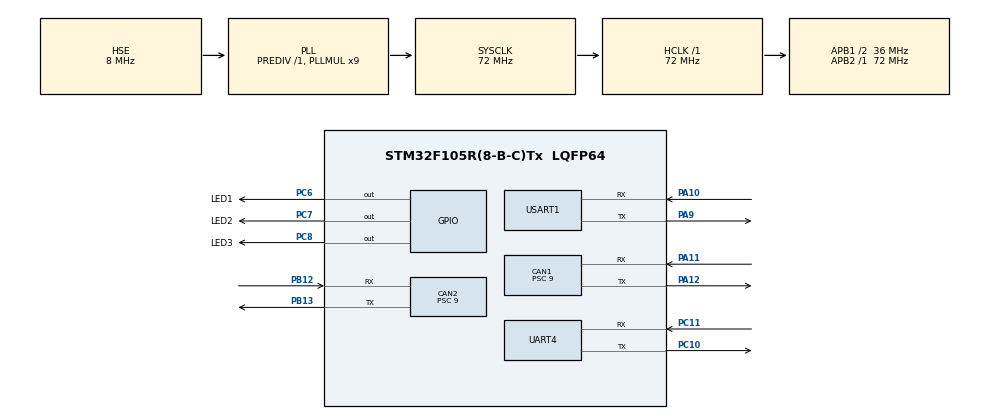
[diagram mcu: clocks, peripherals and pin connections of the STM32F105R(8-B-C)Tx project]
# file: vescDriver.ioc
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CAN1.BS1=CAN_BS1_13TQ
CAN1.BS2=CAN_BS2_2TQ
CAN1.CalculateTimeBit=4000
CAN1.CalculateTimeQuantum=250.0
CAN1.Prescaler=9
CAN2.BS1=CAN_BS1_13TQ
CAN2.BS2=CAN_BS2_2TQ
CAN2.CalculateTimeBit=4000
CAN2.CalculateTimeQuantum=250.0
CAN2.Prescaler=9
Mcu.Family=STM32F1
Mcu.Name=STM32F105R(8-B-C)Tx
Mcu.Package=LQFP64
NVIC.CAN1_RX0_IRQn=true\:0\:0\:false\:false\:true\:true
NVIC.CAN1_RX1_IRQn=true\:0\:0\:false\:false\:true\:true
NVIC.CAN1_SCE_IRQn=true\:0\:0\:false\:false\:true\:true
NVIC.CAN1_TX_IRQn=true\:0\:0\:false\:false\:true\:true
NVIC.CAN2_RX0_IRQn=true\:0\:0\:false\:false\:true\:true
NVIC.CAN2_RX1_IRQn=true\:0\:0\:false\:false\:true\:true
NVIC.CAN2_SCE_IRQn=true\:0\:0\:false\:false\:true\:true
NVIC.CAN2_TX_IRQn=true\:0\:0\:false\:false\:true\:true
NVIC.PriorityGroup=NVIC_PRIORITYGROUP_4
NVIC.UART4_IRQn=true\:0\:0\:false\:false\:true\:true
PA10.Mode=Asynchronous
PA10.Signal=USART1_RX
PA11.Mode=Master
PA11.Signal=CAN1_RX
PA12.Mode=Master
PA12.Signal=CAN1_TX
PA13.Mode=Serial_Wire
PA13.Signal=SYS_JTMS-SWDIO
PA14.Mode=Serial_Wire
PA14.Signal=SYS_JTCK-SWCLK
PA9.Mode=Asynchronous
PA9.Signal=USART1_TX
PB12.Mode=Slave
PB12.Signal=CAN2_RX
PB13.Mode=Slave
PB13.Signal=CAN2_TX
PC10.Mode=Asynchronous
PC10.Signal=UART4_TX
PC11.Mode=Asynchronous
PC11.Signal=UART4_RX
PC6.GPIO_Label=LED1
PC6.Signal=GPIO_Output
PC7.GPIO_Label=LED2
PC7.Signal=GPIO_Output
PC8.GPIO_Label=LED3
PC8.Signal=GPIO_Output
PD0-OSC_IN.Mode=HSE-External-Oscillator
PD0-OSC_IN.Signal=RCC_OSC_IN
PD1-OSC_OUT.Mode=HSE-External-Oscillator
PD1-OSC_OUT.Signal=RCC_OSC_OUT
ProjectManager.HeapSize=0x200
ProjectManager.StackSize=0x400
ProjectManager.TargetToolchain=Makefile
RCC.ADCPresc=RCC_ADCPCLK2_DIV6
RCC.AHBFreq_Value=72000000
RCC.APB1CLKDivider=RCC_HCLK_DIV2
RCC.APB1Freq_Value=36000000
RCC.APB1TimFreq_Value=72000000
RCC.APB2Freq_Value=72000000
RCC.APB2TimFreq_Value=72000000
RCC.HCLKFreq_Value=72000000
RCC.PLLMUL=RCC_PLL_MUL9
RCC.PLLSourceVirtual=RCC_PLLSOURCE_HSE
RCC.SYSCLKFreq_VALUE=72000000
RCC.SYSCLKSource=RCC_SYSCLKSOURCE_PLLCLK
RCC.USBFreq_Value=48000000
UART4.VirtualMode=Asynchronous
USART1.VirtualMode=VM_ASYNC
board=vescDriver

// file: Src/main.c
/**
  ******************************************************************************
  * @file           : main.c
  * @brief          : Main program body
  ******************************************************************************
  ** This notice applies to any and all portions of this file
  * that are not between comment pairs USER CODE BEGIN and
  * USER CODE END. Other portions of this file, whether
  * inserted by the user or by software development tools
  * are owned by their respective copyright owners.
  *
  * COPYRIGHT(c) 2018 STMicroelectronics
  *
  * Redistribution and use in source and binary forms, with or without modification,
  * are permitted provided that the following conditions are met:
  *   1. Redistributions of source code must retain the above copyright notice,
  *      this list of conditions and the following disclaimer.
  *   2. Redistributions in binary form must reproduce the above copyright notice,
  *      this list of conditions and the following disclaimer in the documentation
  *      and/or other materials provided with the distribution.
  *   3. Neither the name of STMicroelectronics nor the names of its contributors
  *      may be used to endorse or promote products derived from this software
  *      without specific prior written permission.
  *
  * THIS SOFTWARE IS PROVIDED BY THE COPYRIGHT HOLDERS AND CONTRIBUTORS "AS IS"
  * AND ANY EXPRESS OR IMPLIED WARRANTIES, INCLUDING, BUT NOT LIMITED TO, THE
  * IMPLIED WARRANTIES OF MERCHANTABILITY AND FITNESS FOR A PARTICULAR PURPOSE ARE
  * DISCLAIMED. IN NO EVENT SHALL THE COPYRIGHT HOLDER OR CONTRIBUTORS BE LIABLE
  * FOR ANY DIRECT, INDIRECT, INCIDENTAL, SPECIAL, EXEMPLARY, OR CONSEQUENTIAL
  * DAMAGES (INCLUDING, BUT NOT LIMITED TO, PROCUREMENT OF SUBSTITUTE GOODS OR
  * SERVICES; LOSS OF USE, DATA, OR PROFITS; OR BUSINESS INTERRUPTION) HOWEVER
  * CAUSED AND ON ANY THEORY OF LIABILITY, WHETHER IN CONTRACT, STRICT LIABILITY,
  * OR TORT (INCLUDING NEGLIGENCE OR OTHERWISE) ARISING IN ANY WAY OUT OF THE USE
  * OF THIS SOFTWARE, EVEN IF ADVISED OF THE POSSIBILITY OF SUCH DAMAGE.
  *
  ******************************************************************************
  */
#include "main.h"
#include "stm32f1xx_hal.h"

/* USER CODE BEGIN Includes */
#include "globals.h"
#include "usrMain.h"
/* USER CODE END Includes */

CAN_HandleTypeDef hcan1;
CAN_HandleTypeDef hcan2;

UART_HandleTypeDef huart4;
UART_HandleTypeDef huart1;

/* USER CODE BEGIN PV */
/* Private variables ---------------------------------------------------------*/

/* USER CODE END PV */

void SystemClock_Config(void);
static void MX_GPIO_Init(void);
static void MX_CAN1_Init(void);
static void MX_USART1_UART_Init(void);
static void MX_UART4_Init(void);
static void MX_CAN2_Init(void);

/* USER CODE BEGIN PFP */
/* Private function prototypes -----------------------------------------------*/

/* USER CODE END PFP */

int main(void)
{

  /* MCU Configuration----------------------------------------------------------*/

  /* Reset of all peripherals, Initializes the Flash interface and the Systick. */
  HAL_Init();

  /* Configure the system clock */
  SystemClock_Config();

  /* Initialize all configured peripherals */
  MX_GPIO_Init();
  MX_CAN1_Init();
  MX_USART1_UART_Init();
  MX_UART4_Init();
  MX_CAN2_Init();
  /* USER CODE BEGIN 2 */
	can1Handle = &hcan1;
	can2Handle = &hcan2;
	uart1Handle = &huart1;
	uart4Handle = &huart4;
	usrMain();
  /* USER CODE END 2 */

  /* Infinite loop */
  while (1)
  {

  }

}

void SystemClock_Config(void)
{

  RCC_OscInitTypeDef RCC_OscInitStruct;
  RCC_ClkInitTypeDef RCC_ClkInitStruct;

    /**Initializes the CPU, AHB and APB busses clocks
    */
  RCC_OscInitStruct.OscillatorType = RCC_OSCILLATORTYPE_HSE;
  RCC_OscInitStruct.HSEState = RCC_HSE_ON;
  RCC_OscInitStruct.HSEPredivValue = RCC_HSE_PREDIV_DIV1;
  RCC_OscInitStruct.HSIState = RCC_HSI_ON;
  RCC_OscInitStruct.Prediv1Source = RCC_PREDIV1_SOURCE_HSE;
  RCC_OscInitStruct.PLL.PLLState = RCC_PLL_ON;
  RCC_OscInitStruct.PLL.PLLSource = RCC_PLLSOURCE_HSE;
  RCC_OscInitStruct.PLL.PLLMUL = RCC_PLL_MUL9;
  RCC_OscInitStruct.PLL2.PLL2State = RCC_PLL_NONE;
  if (HAL_RCC_OscConfig(&RCC_OscInitStruct) != HAL_OK)
  {
    _Error_Handler(__FILE__, __LINE__);
  }

    /**Initializes the CPU, AHB and APB busses clocks
    */
  RCC_ClkInitStruct.ClockType = RCC_CLOCKTYPE_HCLK|RCC_CLOCKTYPE_SYSCLK
                              |RCC_CLOCKTYPE_PCLK1|RCC_CLOCKTYPE_PCLK2;
  RCC_ClkInitStruct.SYSCLKSource = RCC_SYSCLKSOURCE_PLLCLK;
  RCC_ClkInitStruct.AHBCLKDivider = RCC_SYSCLK_DIV1;
  RCC_ClkInitStruct.APB1CLKDivider = RCC_HCLK_DIV2;
  RCC_ClkInitStruct.APB2CLKDivider = RCC_HCLK_DIV1;

  if (HAL_RCC_ClockConfig(&RCC_ClkInitStruct, FLASH_LATENCY_2) != HAL_OK)
  {
    _Error_Handler(__FILE__, __LINE__);
  }

    /**Configure the Systick interrupt time
    */
  HAL_SYSTICK_Config(HAL_RCC_GetHCLKFreq()/1000);

    /**Configure the Systick
    */
  HAL_SYSTICK_CLKSourceConfig(SYSTICK_CLKSOURCE_HCLK);

    /**Configure the Systick interrupt time
    */
  __HAL_RCC_PLLI2S_ENABLE();

  /* SysTick_IRQn interrupt configuration */
  HAL_NVIC_SetPriority(SysTick_IRQn, 0, 0);
}

/* CAN1 init function */
static void MX_CAN1_Init(void)
{

  hcan1.Instance = CAN1;
  hcan1.Init.Prescaler = 9;
  hcan1.Init.Mode = CAN_MODE_NORMAL;
  hcan1.Init.SJW = CAN_SJW_1TQ;
  hcan1.Init.BS1 = CAN_BS1_13TQ;
  hcan1.Init.BS2 = CAN_BS2_2TQ;
  hcan1.Init.TTCM = DISABLE;
  hcan1.Init.ABOM = DISABLE;
  hcan1.Init.AWUM = DISABLE;
  hcan1.Init.NART = DISABLE;
  hcan1.Init.RFLM = DISABLE;
  hcan1.Init.TXFP = DISABLE;
  if (HAL_CAN_Init(&hcan1) != HAL_OK)
  {
    _Error_Handler(__FILE__, __LINE__);
  }

}

/* CAN2 init function */
static void MX_CAN2_Init(void)
{

  hcan2.Instance = CAN2;
  hcan2.Init.Prescaler = 9;
  hcan2.Init.Mode = CAN_MODE_NORMAL;
  hcan2.Init.SJW = CAN_SJW_1TQ;
  hcan2.Init.BS1 = CAN_BS1_13TQ;
  hcan2.Init.BS2 = CAN_BS2_2TQ;
  hcan2.Init.TTCM = DISABLE;
  hcan2.Init.ABOM = DISABLE;
  hcan2.Init.AWUM = DISABLE;
  hcan2.Init.NART = DISABLE;
  hcan2.Init.RFLM = DISABLE;
  hcan2.Init.TXFP = DISABLE;
  if (HAL_CAN_Init(&hcan2) != HAL_OK)
  {
    _Error_Handler(__FILE__, __LINE__);
  }

}

/* UART4 init function */
static void MX_UART4_Init(void)
{

  huart4.Instance = UART4;
  huart4.Init.BaudRate = 115200;
  huart4.Init.WordLength = UART_WORDLENGTH_8B;
  huart4.Init.StopBits = UART_STOPBITS_1;
  huart4.Init.Parity = UART_PARITY_NONE;
  huart4.Init.Mode = UART_MODE_TX_RX;
  huart4.Init.HwFlowCtl = UART_HWCONTROL_NONE;
  huart4.Init.OverSampling = UART_OVERSAMPLING_16;
  if (HAL_UART_Init(&huart4) != HAL_OK)
  {
    _Error_Handler(__FILE__, __LINE__);
  }

}

/* USART1 init function */
static void MX_USART1_UART_Init(void)
{

  huart1.Instance = USART1;
  huart1.Init.BaudRate = 115200;
  huart1.Init.WordLength = UART_WORDLENGTH_8B;
  huart1.Init.StopBits = UART_STOPBITS_1;
  huart1.Init.Parity = UART_PARITY_NONE;
  huart1.Init.Mode = UART_MODE_TX_RX;
  huart1.Init.HwFlowCtl = UART_HWCONTROL_NONE;
  huart1.Init.OverSampling = UART_OVERSAMPLING_16;
  if (HAL_UART_Init(&huart1) != HAL_OK)
  {
    _Error_Handler(__FILE__, __LINE__);
  }

}

/** Configure pins as
        * Analog
        * Input
        * Output
        * EVENT_OUT
        * EXTI
*/
static void MX_GPIO_Init(void)
{

  GPIO_InitTypeDef GPIO_InitStruct;

  /* GPIO Ports Clock Enable */
  __HAL_RCC_GPIOD_CLK_ENABLE();
  __HAL_RCC_GPIOB_CLK_ENABLE();
  __HAL_RCC_GPIOC_CLK_ENABLE();
  __HAL_RCC_GPIOA_CLK_ENABLE();

  /*Configure GPIO pin Output Level */
  HAL_GPIO_WritePin(GPIOC, LED1_Pin|LED2_Pin|LED3_Pin, GPIO_PIN_RESET);

  /*Configure GPIO pins : LED1_Pin LED2_Pin LED3_Pin */
  GPIO_InitStruct.Pin = LED1_Pin|LED2_Pin|LED3_Pin;
  GPIO_InitStruct.Mode = GPIO_MODE_OUTPUT_PP;
  GPIO_InitStruct.Speed = GPIO_SPEED_FREQ_LOW;
  HAL_GPIO_Init(GPIOC, &GPIO_InitStruct);

}

void _Error_Handler(char *file, int line)
{
  while(1)
  {
  }
}

/************************ (C) COPYRIGHT STMicroelectronics *****END OF FILE****/
